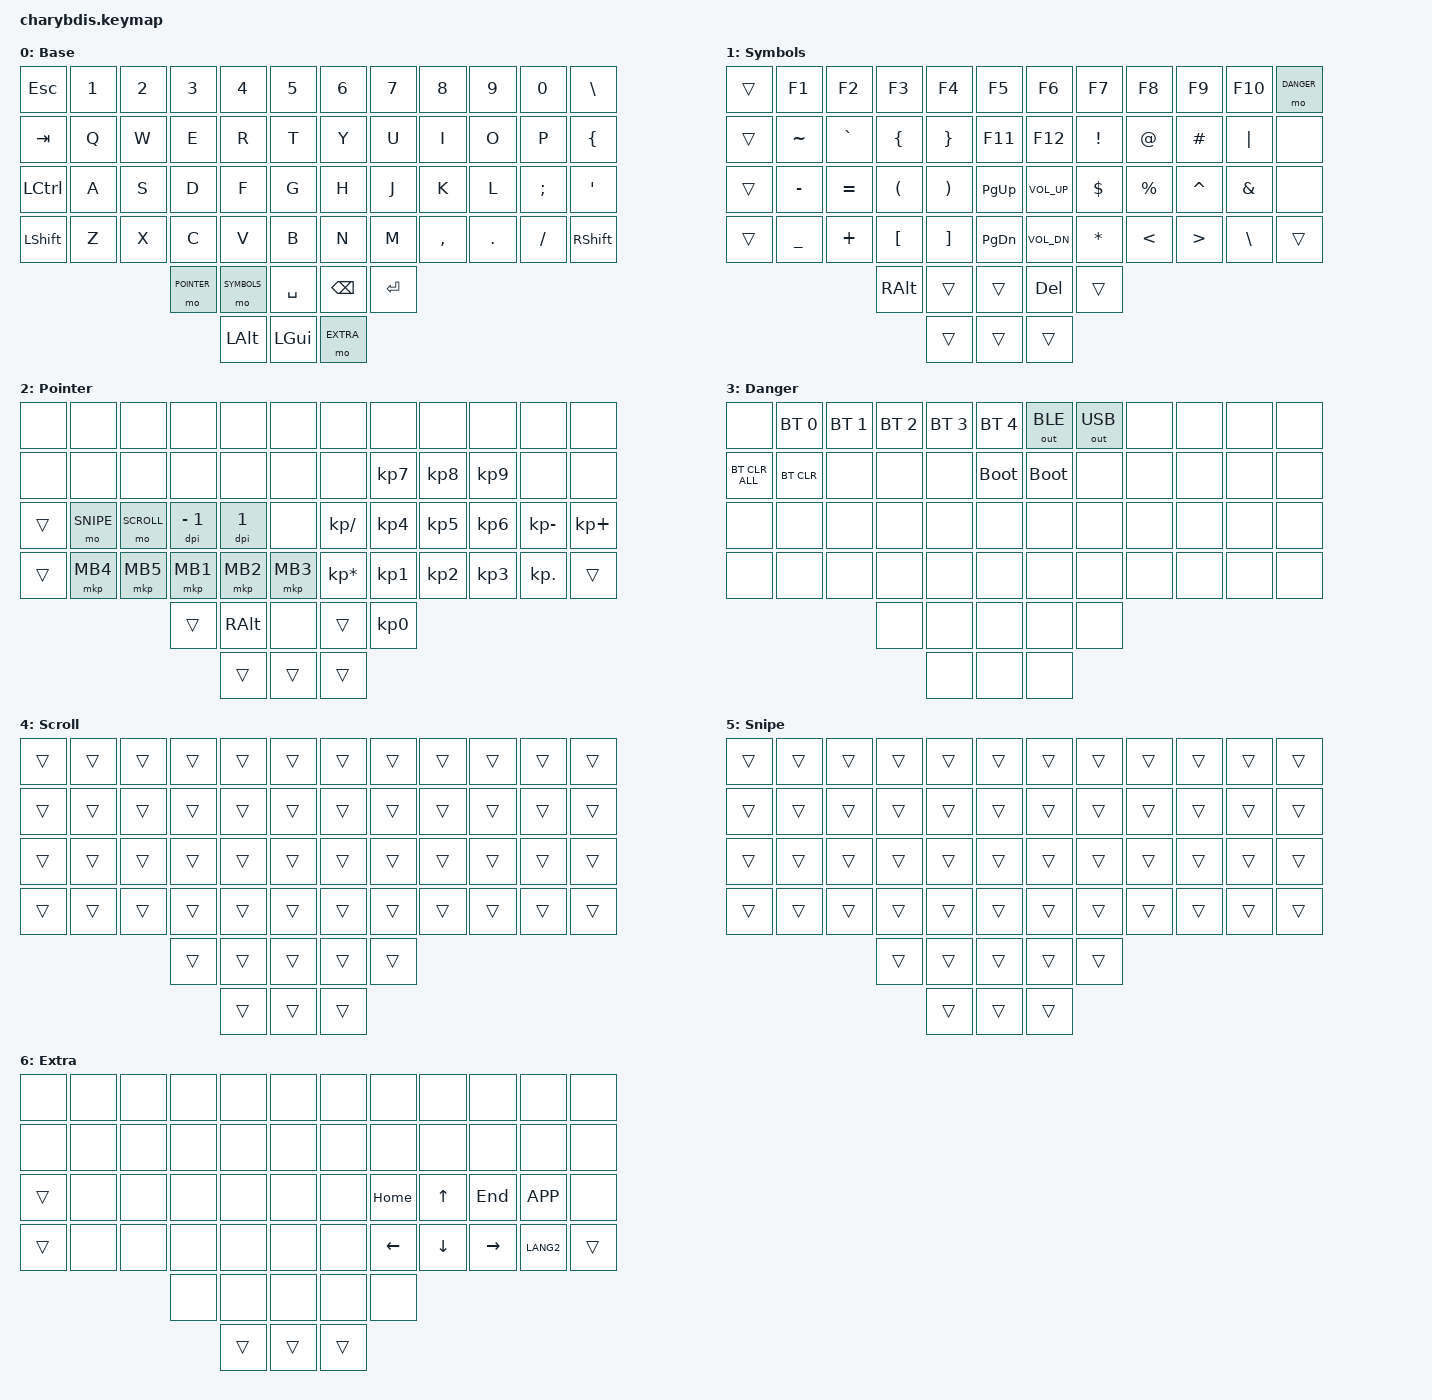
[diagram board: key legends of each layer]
#include <behaviors.dtsi>
#include <dt-bindings/zmk/bt.h>
#include <dt-bindings/zmk/keys.h>
#include <dt-bindings/zmk/mouse.h>
#include <dt-bindings/zmk/outputs.h>

#define BASE 0
/* Also a scroll layer: see the listener in charybdis_dongle.overlay. */
#define SYMBOLS 1
// #define UTILITY 2
#define POINTER 2
#define DANGER 3
/*
 * Pointer mode layers. These carry no key bindings; they exist so the
 * trackball's input processor chain can be swapped while a key is held.
 *
 * The listener that reacts to them, and to SYMBOLS, lives in
 * charybdis_dongle.overlay and spells these numbers out, because devicetree
 * is preprocessed before Kconfig and so cannot be made conditional on the
 * shield. Keep the two in sync by hand.
 */
#define SCROLL 4
#define SNIPE 5
/* Keyboard-only layer, placed last so the listener's layer numbers stay put. */
#define EXTRA 6

/*
 * Shared by both halves and the dongle, so nothing here may touch nodes that
 * only exist on one of them. Underglow, encoders and the unused SPI bus are
 * disabled in the shield files instead.
 */
/ {
    keymap {
        compatible = "zmk,keymap";

        base_layer {
            display-name = "Base";
            bindings = <
&kp ESC       &kp N1       &kp N2       &kp N3       &kp N4       &kp N5          &kp N6       &kp N7       &kp N8       &kp N9       &kp N0          &kp BSLH
&kp TAB       &kp Q        &kp W        &kp E        &kp R        &kp T           &kp Y        &kp U        &kp I        &kp O        &kp P           &kp LEFT_BRACE
&kp LCTRL     &kp A        &kp S        &kp D        &kp F        &kp G           &kp H        &kp J        &kp K        &kp L        &kp SEMI        &kp SQT
&kp LSHIFT    &kp Z        &kp X        &kp C        &kp V        &kp B           &kp N        &kp M        &kp COMMA    &kp PERIOD   &kp FSLH        &kp RSHIFT
                                        &mo POINTER  &mo SYMBOLS  &kp SPACE       &kp BACKSPACE &kp ENTER
                                                     &kp LALT     &kp LGUI        &mo EXTRA
            >;
        };

        symbols_layer {
            display-name = "Symbols";
            /* Hangul/English is POINTER + SYMBOLS together: RALT sits on the
               POINTER key here and on the SYMBOLS key in the pointer layer,
               so whichever is pressed second fires it, with no combo delay. */
            bindings = <
&trans     &kp F1          &kp F2     &kp F3                &kp F4                  &kp F5          &kp F6       &kp F7       &kp F8        &kp F9           &kp F10   &mo DANGER
&trans     &kp TILDE       &kp GRAVE  &kp LEFT_BRACE        &kp RIGHT_BRACE         &kp F11         &kp F12      &kp EXCL     &kp AT       &kp HASH         &kp PIPE  &none
&trans     &kp MINUS       &kp EQUAL  &kp LEFT_PARENTHESIS  &kp RIGHT_PARENTHESIS   &kp PAGE_UP     &kp C_VOL_UP &kp DLLR     &kp PRCNT     &kp CARET        &kp AMPS  &none
&trans     &kp UNDERSCORE  &kp PLUS   &kp LEFT_BRACKET      &kp RIGHT_BRACKET       &kp PAGE_DOWN   &kp C_VOL_DN &kp ASTRK    &kp LESS_THAN &kp GREATER_THAN &kp BSLH  &trans
                                      &kp RALT              &trans                  &trans          &kp DELETE &trans
                                                            &trans                  &trans          &trans
            >;
        };

        /*
        utility_layer {
            display-name = "Utility";
            bindings = <
&kp ESC          &kp F1       &kp F2             &kp F3          &kp F4             &kp T              &kp F6       &kp F7       &kp F8       &kp F9       &kp F10      &to BASE
&kp D            &kp N        &kp LC(LG(L))      &kp LG(LA(L))   &kp LA(Y)           &kp LA(X)          &kp Y        &kp U        &kp I        &kp O        &kp P        &kp BSLH
&kp LG(R)        &kp A        &mt LALT LS(LG(LEFT_BRACKET)) &kp LG(B) &kp LS(LG(RIGHT_BRACKET)) &kp LS(BACKSPACE) &kp H &kp J &kp K &kp L &kp SEMI &kp SQT
&mo POINTER      &kp Z        &kp J              &kp SPACE       &kp L               &kp BACKSPACE      &kp LG(C)    &kp LA(V)    &kp COMMA    &kp PERIOD   &kp FSLH     &kp LGUI
                                                     &kp LSHIFT   &kp LA(V)   &kp ENTER    &kp SPACE   &kp BACKSPACE
                                                                  &kp LGUI    &kp LCTRL    &kp LALT
            >;
        };
        */

        pointer_layer {
            display-name = "Pointer";
            /* Snipe and drag scroll are layer based. CPI stepping is back on
               the keys it used to sit on, now cycling the sensor's own CPI
               through the values in charybdis_layout.dtsi. */
            bindings = <
&none   &none               &none                &none                  &none                  &none      &none           &none     &none     &none     &none        &none
&none   &none               &none                &none                  &none                  &none      &none           &kp KP_N7 &kp KP_N8 &kp KP_N9 &none        &none
&trans  &mo SNIPE           &mo SCROLL           &dpi (-1)              &dpi 1                 &none      &kp KP_DIVIDE   &kp KP_N4 &kp KP_N5 &kp KP_N6 &kp KP_MINUS &kp KP_PLUS
&trans  &mkp MB4            &mkp MB5             &mkp MB1               &mkp MB2               &mkp MB3   &kp KP_MULTIPLY &kp KP_N1 &kp KP_N2 &kp KP_N3 &kp KP_DOT   &trans
                                                 &trans                 &kp RALT               &none      &trans          &kp KP_N0
                                                                        &trans                 &trans     &trans
            >;
        };

        danger_layer {
            display-name = "Danger";
            bindings = <
&none           &bt BT_SEL 0  &bt BT_SEL 1  &bt BT_SEL 2  &bt BT_SEL 3  &bt BT_SEL 4    &out OUT_BLE &out OUT_USB &none  &none  &none  &none
&bt BT_CLR_ALL  &bt BT_CLR    &none         &none         &none         &bootloader     &bootloader  &none         &none  &none  &none  &none
&none           &none         &none         &none         &none         &none           &none        &none        &none  &none  &none  &none
&none           &none         &none         &none         &none         &none           &none        &none        &none  &none  &none  &none
                                           &none         &none         &none           &none        &none
                                                         &none         &none           &none
            >;
        };

        /*
         * Pointer mode layers. Fully transparent: the trackball's input
         * listener reacts to them, the key matrix does not.
         */
        scroll_layer {
            display-name = "Scroll";
            bindings = <
&trans  &trans  &trans  &trans  &trans  &trans    &trans  &trans  &trans  &trans  &trans  &trans
&trans  &trans  &trans  &trans  &trans  &trans    &trans  &trans  &trans  &trans  &trans  &trans
&trans  &trans  &trans  &trans  &trans  &trans    &trans  &trans  &trans  &trans  &trans  &trans
&trans  &trans  &trans  &trans  &trans  &trans    &trans  &trans  &trans  &trans  &trans  &trans
                        &trans  &trans  &trans    &trans  &trans
                                &trans  &trans    &trans
            >;
        };

        snipe_layer {
            display-name = "Snipe";
            bindings = <
&trans  &trans  &trans  &trans  &trans  &trans    &trans  &trans  &trans  &trans  &trans  &trans
&trans  &trans  &trans  &trans  &trans  &trans    &trans  &trans  &trans  &trans  &trans  &trans
&trans  &trans  &trans  &trans  &trans  &trans    &trans  &trans  &trans  &trans  &trans  &trans
&trans  &trans  &trans  &trans  &trans  &trans    &trans  &trans  &trans  &trans  &trans  &trans
                        &trans  &trans  &trans    &trans  &trans
                                &trans  &trans    &trans
            >;
        };

        extra_layer {
            display-name = "Extra";
            bindings = <
&none   &none   &none   &none   &none   &none      &none   &none   &none   &none   &none   &none
&none   &none   &none   &none   &none   &none      &none   &none   &none   &none   &none   &none
&trans  &none   &none   &none   &none   &none      &none   &kp HOME &kp UP &kp END &kp K_APP &none
&trans   &none   &none   &none   &none   &none      &none   &kp LEFT &kp DOWN &kp RIGHT &kp LANG2 &trans
                        &none   &none   &none      &none   &none
                                &trans  &trans     &trans
            >;
        };

    };
};
